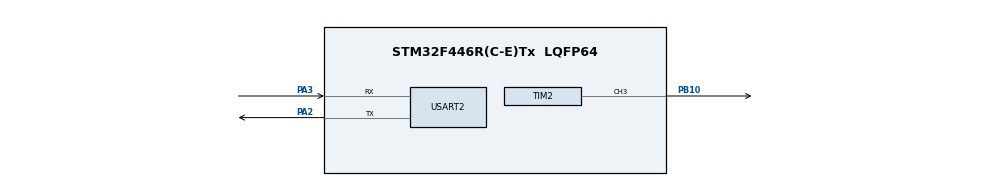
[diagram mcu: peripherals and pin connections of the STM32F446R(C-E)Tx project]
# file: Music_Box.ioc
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Mcu.Family=STM32F4
Mcu.Name=STM32F446R(C-E)Tx
Mcu.Package=LQFP64
NVIC.PriorityGroup=NVIC_PRIORITYGROUP_4
NVIC.TIM2_IRQn=true\:0\:0\:false\:false\:true\:true\:true\:true
NVIC.USART2_IRQn=true\:0\:0\:false\:false\:true\:true\:true\:true
PA2.Mode=Asynchronous
PA2.Signal=USART2_TX
PA3.Mode=Asynchronous
PA3.Signal=USART2_RX
PB10.Signal=S_TIM2_CH3
ProjectManager.HeapSize=0x200
ProjectManager.StackSize=0x400
ProjectManager.TargetToolchain=STM32CubeIDE
RCC.CortexFreq_Value=16000000
RCC.USBFreq_Value=96000000
RCC.VCOOutputFreq_Value=192000000
SH.S_TIM2_CH3.0=TIM2_CH3,PWM Generation3 CH3
TIM2.AutoReloadPreload=TIM_AUTORELOAD_PRELOAD_ENABLE
TIM2.Channel-PWM\ Generation3\ CH3=TIM_CHANNEL_3
TIM2.Period=383
TIM2.Prescaler=1999
TIM2.Pulse-PWM\ Generation3\ CH3=191
USART2.VirtualMode=VM_ASYNC
VP_TIM2_VS_ClockSourceINT.Mode=Internal
board=custom

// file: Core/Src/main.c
/* USER CODE BEGIN Header */
/**
 ******************************************************************************
 * @file           : main.c
 * @brief          : Main program body
 ******************************************************************************
 * @attention
 *
 * Copyright (c) 2024 STMicroelectronics.
 * All rights reserved.
 *
 * This software is licensed under terms that can be found in the LICENSE file
 * in the root directory of this software component.
 * If no LICENSE file comes with this software, it is provided AS-IS.
 *
 ******************************************************************************
 */
/* USER CODE END Header */
#include "main.h"
#include "tim.h"
#include "usart.h"
#include "gpio.h"

void SystemClock_Config(void);
/* USER CODE BEGIN PFP */

uint32_t getNoteFrequency(char note, int octave);
int _write(int fd, char*ptr, int len);
void playConstantBuzz(void);

/* USER CODE END PFP */

int main(void)
{

	/* MCU Configuration--------------------------------------------------------*/

	/* Reset of all peripherals, Initializes the Flash interface and the Systick. */
	HAL_Init();

	/* Configure the system clock */
	SystemClock_Config();

	/* Initialize all configured peripherals */
	MX_GPIO_Init();
	MX_USART2_UART_Init();
	MX_TIM2_Init();
	/* USER CODE BEGIN 2 */
	HAL_TIM_PWM_Start(&htim2, TIM_CHANNEL_3);
	playNoteFrequency(440);  // Constant frequency test
	playConstantBuzz();

	/* USER CODE END 2 */

	/* Infinite loop */
	while (1)
	{

		/* USER CODE BEGIN 3 */
		playConstantBuzz();
		//HAL_UART_Transmit(&huart2, (uint8_t*)debugMessage, strlen(debugMessage), 100);
	}
	/* USER CODE END 3 */
}

void SystemClock_Config(void)
{
	RCC_OscInitTypeDef RCC_OscInitStruct = {0};
	RCC_ClkInitTypeDef RCC_ClkInitStruct = {0};

	/** Configure the main internal regulator output voltage
	 */
	__HAL_RCC_PWR_CLK_ENABLE();
	__HAL_PWR_VOLTAGESCALING_CONFIG(PWR_REGULATOR_VOLTAGE_SCALE3);

	/** Initializes the RCC Oscillators according to the specified parameters
	 * in the RCC_OscInitTypeDef structure.
	 */
	RCC_OscInitStruct.OscillatorType = RCC_OSCILLATORTYPE_HSI;
	RCC_OscInitStruct.HSIState = RCC_HSI_ON;
	RCC_OscInitStruct.HSICalibrationValue = RCC_HSICALIBRATION_DEFAULT;
	RCC_OscInitStruct.PLL.PLLState = RCC_PLL_NONE;
	if (HAL_RCC_OscConfig(&RCC_OscInitStruct) != HAL_OK)
	{
		Error_Handler();
	}

	/** Initializes the CPU, AHB and APB buses clocks
	 */
	RCC_ClkInitStruct.ClockType = RCC_CLOCKTYPE_HCLK|RCC_CLOCKTYPE_SYSCLK
			|RCC_CLOCKTYPE_PCLK1|RCC_CLOCKTYPE_PCLK2;
	RCC_ClkInitStruct.SYSCLKSource = RCC_SYSCLKSOURCE_HSI;
	RCC_ClkInitStruct.AHBCLKDivider = RCC_SYSCLK_DIV1;
	RCC_ClkInitStruct.APB1CLKDivider = RCC_HCLK_DIV1;
	RCC_ClkInitStruct.APB2CLKDivider = RCC_HCLK_DIV1;

	if (HAL_RCC_ClockConfig(&RCC_ClkInitStruct, FLASH_LATENCY_0) != HAL_OK)
	{
		Error_Handler();
	}
}

/* USER CODE BEGIN 4 */
void HAL_UART_RxCpltCallback(UART_HandleTypeDef *huart)
{
	char receivedData[2];
	HAL_UART_Receive_IT(&huart2,(uint8_t*)receivedData, 2);

	char note = receivedData[0];
	int octave = receivedData[1]-'1';

	uint32_t frequency = getNoteFrequency(note,octave);

	playNoteFrequency(frequency);
}

uint32_t getNoteFrequency(char note, int octave)
{
	uint32_t frequencies[12][5] = {
			{32, 65, 130, 261, 523},  // C
			{34, 69, 138, 277, 554},  // C#
			{36, 73, 146, 293, 587},  // D
			{38, 77, 155, 311, 622},  // D#
			{41, 82, 164, 329, 659},  // E
			{43, 87, 174, 349, 698},  // F
			{46, 92, 185, 369, 739},  // F#
			{49, 98, 196, 392, 784},  // G
			{52, 104, 208, 415, 830}, // G#
			{55, 110, 220, 440, 880}, // A
			{58, 116, 233, 466, 932}, // A#
			{61, 123, 246, 493, 987}  // B
	};

	int noteIndex = getNoteIndex(note);

	if(noteIndex == -1)
	{
		return 0;
	}

	return frequencies[noteIndex][octave];
}

int _write(int fd, char *ptr, int len)
{
	HAL_StatusTypeDef status = HAL_UART_Transmit(&huart2, (uint8_t*)ptr, len, HAL_MAX_DELAY);
	return (status == HAL_OK) ? len : -1;
}

void playConstantBuzz(void)
{
	uint32_t frequency = 2;  // Set the frequency to 440 Hz (A4 note)

	/* Calculate the timer period for the given frequency */
	uint32_t timerPeriod = (SystemCoreClock / (frequency * 2)) - 1;

	/* Set the calculated period */
	__HAL_TIM_SET_AUTORELOAD(&htim2, 5);

	/* Set the pulse width to 50% duty cycle */
	uint32_t pulseValue = 5 / 2;
	__HAL_TIM_SET_COMPARE(&htim2, TIM_CHANNEL_3, pulseValue);

	/* Start the PWM signal */
	HAL_TIM_PWM_Start(&htim2, TIM_CHANNEL_3);
}

/* USER CODE END 4 */

void Error_Handler(void)
{
	__disable_irq();
	while (1)
	{
	}
}
